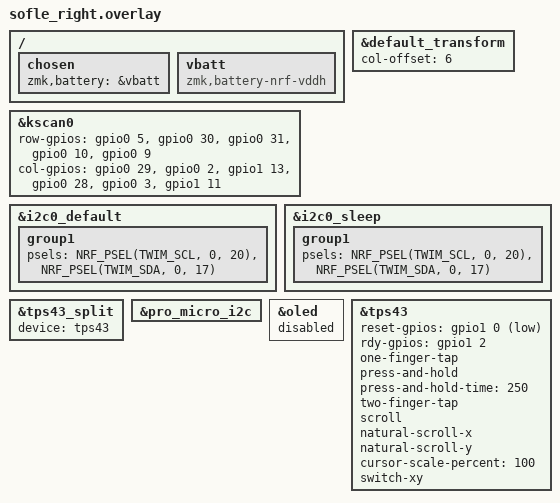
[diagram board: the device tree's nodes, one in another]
/*
 * Copyright (c) 2020 Ryan Cross
 *
 * SPDX-License-Identifier: MIT
 */

#include "sofle.dtsi"

&default_transform {
    col-offset = <6>;
};

&kscan0 {
    // Schematic nets row0 through row4.
    row-gpios
        = <&gpio0 5 (GPIO_ACTIVE_HIGH | GPIO_PULL_DOWN)>
        , <&gpio0 30 (GPIO_ACTIVE_HIGH | GPIO_PULL_DOWN)>
        , <&gpio0 31 (GPIO_ACTIVE_HIGH | GPIO_PULL_DOWN)>
        , <&gpio0 10 (GPIO_ACTIVE_HIGH | GPIO_PULL_DOWN)>
        , <&gpio0 9 (GPIO_ACTIVE_HIGH | GPIO_PULL_DOWN)>
        ;

    // Schematic nets col0 through col5.
    col-gpios
        = <&gpio0 29 GPIO_ACTIVE_HIGH>
        , <&gpio0 2 GPIO_ACTIVE_HIGH>
        , <&gpio1 13 GPIO_ACTIVE_HIGH>
        , <&gpio0 28 GPIO_ACTIVE_HIGH>
        , <&gpio0 3 GPIO_ACTIVE_HIGH>
        , <&gpio1 11 GPIO_ACTIVE_HIGH>
        ;
};

// Trackpad I2C pins: SCL=P0.20, SDA=P0.17.
&i2c0_default {
    group1 {
        psels = <NRF_PSEL(TWIM_SCL, 0, 20)>,
                <NRF_PSEL(TWIM_SDA, 0, 17)>;
    };
};

&i2c0_sleep {
    group1 {
        psels = <NRF_PSEL(TWIM_SCL, 0, 20)>,
                <NRF_PSEL(TWIM_SDA, 0, 17)>;
    };
};

/ {
    chosen {
      zmk,battery = &vbatt;
    };

    vbatt: vbatt {
        compatible = "zmk,battery-nrf-vddh";
    };
};

&tps43_split {
    status = "okay";
    device = <&tps43>;
};


&pro_micro_i2c {
    status = "okay";
};

&oled {
    status = "disabled";
};

&tps43 {
    status = "okay";

    // The IQS5xx driver asserts reset with logical 1; RST is active low.
    reset-gpios = <&gpio1 0 GPIO_ACTIVE_LOW>;
    rdy-gpios = <&gpio1 2 GPIO_ACTIVE_HIGH>;

    /*
     * Potentially non-exhaustive list of configuration options.
     * See: dts/bindings/input/azoteq,iqs5xx-common.yaml for a full list.
     */
    one-finger-tap;
    press-and-hold;
    press-and-hold-time = <250>;
    two-finger-tap;

    scroll;
    // Preserve the old driver's raw X and inverted Y scroll directions.
    natural-scroll-x;
    natural-scroll-y;

    cursor-scale-percent = <100>;

    switch-xy;
};
